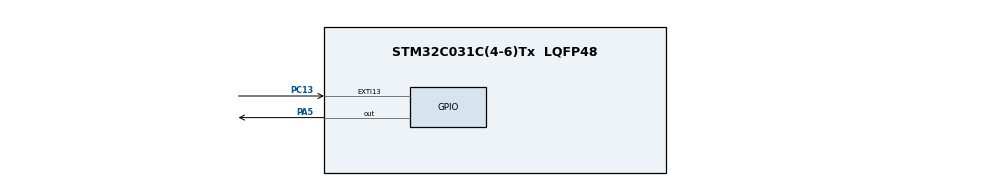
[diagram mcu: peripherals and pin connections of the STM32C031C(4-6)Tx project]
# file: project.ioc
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Mcu.Family=STM32C0
Mcu.Name=STM32C031C(4-6)Tx
Mcu.Package=LQFP48
NUCLEO-C031C6.BUTTON=2
NUCLEO-C031C6.LD4=true
NUCLEO-C031C6.VCP=false
PA13.Signal=DEBUG_SWDIO
PA14-BOOT0.Signal=DEBUG_SWCLK
PA5.Signal=GPIO_Output
PB8.Signal=I2C1_SCL
PB9.Signal=I2C1_SDA
PC13.Signal=GPXTI13
PC14-OSCX_IN\ (PC14).Mode=LSE-External-Oscillator
PC14-OSCX_IN\ (PC14).Signal=RCC_OSCX_IN
PC15-OSCX_OUT\ (PC15).Mode=LSE-External-Oscillator
PC15-OSCX_OUT\ (PC15).Signal=RCC_OSCX_OUT
PF0-OSC_IN\ (PF0).Mode=HSE-External-Oscillator
PF0-OSC_IN\ (PF0).Signal=RCC_OSC_IN
PF1-OSC_OUT\ (PF1).Mode=HSE-External-Oscillator
PF1-OSC_OUT\ (PF1).Signal=RCC_OSC_OUT
ProjectManager.HeapSize=0x200
ProjectManager.StackSize=0x400
ProjectManager.TargetToolchain=STM32CubeIDE
QuantumLeaps.qpc.8.0.0.qpcCcRTEFJjEventOoProcessor=qep
QuantumLeaps.qpc.8.0.0.qpcCcRTEFJjFramework=qf
QuantumLeaps.qpc.8.0.0.qpcCcRTEFJjRealAaTimeOoKernel=qk
QuantumLeaps.qpc.8.0.0.qpcCcRTEFJjSoftwareOotracing=qs
RCC.ADCFreq_Value=48000000
RCC.AHBFreq_Value=48000000
RCC.CortexFreq_Value=48000000
RCC.EXTERNAL_CLOCK_VALUE=12288000
RCC.HCLKFreq_Value=48000000
RCC.HSE_VALUE=48000000
RCC.HSISYSCLKDivider=RCC_HSI_DIV1
RCC.HSI_VALUE=48000000
RCC.SYSCLKFreq_VALUE=48000000
RCC.SYSCLKSource=RCC_SYSCLKSOURCE_HSE
VP_NUCLEO-C031C6_VS_BSP_COMMON.Mode=COMMON
VP_QuantumLeaps.qpc_VS_RTEFJjqpc_8.0.0_8.0.0.Mode=RTEFJjqpc
board=NUCLEO-C031C6

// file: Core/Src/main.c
/* USER CODE BEGIN Header */
/**
  ******************************************************************************
  * @file           : main.c
  * @brief          : Main program body
  ******************************************************************************
  * @attention
  *
  * Copyright (c) 2024 STMicroelectronics.
  * All rights reserved.
  *
  * This software is licensed under terms that can be found in the LICENSE file
  * in the root directory of this software component.
  * If no LICENSE file comes with this software, it is provided AS-IS.
  *
  ******************************************************************************
  */
/* USER CODE END Header */
#include "main.h"

/* USER CODE BEGIN Includes */
#include "qpc.h"
#include "bsp.h"
/* USER CODE END Includes */

void SystemClock_Config(void);
static void MX_GPIO_Init(void);

int main(void)
{

  /* MCU Configuration--------------------------------------------------------*/

  /* Reset of all peripherals, Initializes the Flash interface and the Systick. */
  HAL_Init();

  /* Configure the system clock */
  SystemClock_Config();

  /* Initialize all configured peripherals */
  MX_GPIO_Init();

  /* Initialize leds */
  BSP_LED_Init(LED_GREEN);

  /* Initialize User push-button without interrupt mode. */
  BSP_PB_Init(BUTTON_USER, BUTTON_MODE_GPIO);

  /* Infinite loop */
  /* USER CODE BEGIN WHILE */
  QF_init();
  BSP_init();
  BSP_start();
  QF_run(); // does NOT return
  //#####################################################

  while (1)
  {
    BSP_LED_On(LED_GREEN);
    HAL_Delay(100);
    BSP_LED_Off(LED_GREEN);
    HAL_Delay(300);
    /* USER CODE END WHILE */

  }
}

void SystemClock_Config(void)
{
  RCC_OscInitTypeDef RCC_OscInitStruct = {0};
  RCC_ClkInitTypeDef RCC_ClkInitStruct = {0};

  /** Initializes the RCC Oscillators according to the specified parameters
  * in the RCC_OscInitTypeDef structure.
  */
  RCC_OscInitStruct.OscillatorType = RCC_OSCILLATORTYPE_HSE;
  RCC_OscInitStruct.HSEState = RCC_HSE_ON;
  if (HAL_RCC_OscConfig(&RCC_OscInitStruct) != HAL_OK)
  {
    Error_Handler();
  }

  /** Initializes the CPU, AHB and APB buses clocks
  */
  RCC_ClkInitStruct.ClockType = RCC_CLOCKTYPE_HCLK|RCC_CLOCKTYPE_SYSCLK
                              |RCC_CLOCKTYPE_PCLK1;
  RCC_ClkInitStruct.SYSCLKSource = RCC_SYSCLKSOURCE_HSE;
  RCC_ClkInitStruct.SYSCLKDivider = RCC_SYSCLK_DIV1;
  RCC_ClkInitStruct.AHBCLKDivider = RCC_HCLK_DIV1;
  RCC_ClkInitStruct.APB1CLKDivider = RCC_APB1_DIV1;

  if (HAL_RCC_ClockConfig(&RCC_ClkInitStruct, FLASH_LATENCY_1) != HAL_OK)
  {
    Error_Handler();
  }
}

static void MX_GPIO_Init(void)
{
  GPIO_InitTypeDef GPIO_InitStruct = {0};

  /* GPIO Ports Clock Enable */
  __HAL_RCC_GPIOC_CLK_ENABLE();
  __HAL_RCC_GPIOF_CLK_ENABLE();
  __HAL_RCC_GPIOA_CLK_ENABLE();
  __HAL_RCC_GPIOB_CLK_ENABLE();

  /*Configure GPIO pin Output Level */
  HAL_GPIO_WritePin(GPIOA, GPIO_PIN_5, GPIO_PIN_RESET);

  /*Configure GPIO pin : PC13 */
  GPIO_InitStruct.Pin = GPIO_PIN_13;
  GPIO_InitStruct.Mode = GPIO_MODE_IT_RISING;
  GPIO_InitStruct.Pull = GPIO_NOPULL;
  HAL_GPIO_Init(GPIOC, &GPIO_InitStruct);

  /*Configure GPIO pin : PA5 */
  GPIO_InitStruct.Pin = GPIO_PIN_5;
  GPIO_InitStruct.Mode = GPIO_MODE_OUTPUT_PP;
  GPIO_InitStruct.Pull = GPIO_NOPULL;
  GPIO_InitStruct.Speed = GPIO_SPEED_FREQ_LOW;
  HAL_GPIO_Init(GPIOA, &GPIO_InitStruct);

  /*Configure GPIO pins : PB8 PB9 */
  GPIO_InitStruct.Pin = GPIO_PIN_8|GPIO_PIN_9;
  GPIO_InitStruct.Mode = GPIO_MODE_AF_OD;
  GPIO_InitStruct.Pull = GPIO_NOPULL;
  GPIO_InitStruct.Speed = GPIO_SPEED_FREQ_LOW;
  GPIO_InitStruct.Alternate = GPIO_AF6_I2C1;
  HAL_GPIO_Init(GPIOB, &GPIO_InitStruct);

}

void Error_Handler(void)
{
  __disable_irq();
  while (1)
  {
  }
}
